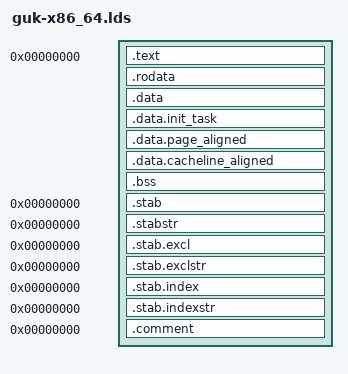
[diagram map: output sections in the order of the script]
/*
 * Copyright (c) 2009, 2011, Oracle and/or its affiliates. All rights reserved.
 * DO NOT ALTER OR REMOVE COPYRIGHT NOTICES OR THIS FILE HEADER.
 *
 * This code is free software; you can redistribute it and/or modify it
 * under the terms of the GNU General Public License version 2 only, as
 * published by the Free Software Foundation.
 *
 * This code is distributed in the hope that it will be useful, but WITHOUT
 * ANY WARRANTY; without even the implied warranty of MERCHANTABILITY or
 * FITNESS FOR A PARTICULAR PURPOSE.  See the GNU General Public License
 * version 2 for more details (a copy is included in the LICENSE file that
 * accompanied this code).
 *
 * You should have received a copy of the GNU General Public License version
 * 2 along with this work; if not, write to the Free Software Foundation,
 * Inc., 51 Franklin St, Fifth Floor, Boston, MA 02110-1301 USA.
 *
 * Please contact Oracle, 500 Oracle Parkway, Redwood Shores, CA 94065 USA
 * or visit www.oracle.com if you need additional information or have any
 * questions.
 */
OUTPUT_FORMAT("elf64-x86-64", "elf64-x86-64", "elf64-x86-64")
OUTPUT_ARCH(i386:x86-64)
ENTRY(_start)
SECTIONS
{
  . = 0x00000000;
  _text = .;			/* Text and read-only data */
  .text : { 

      *(.text)
	      . = ALIGN(8);
	  __init_start = .;
      *(.GUK_init)
	  __init_end = .;
	  *(.gnu.warning)
  } = 0x9090

  _etext = .;			/* End of text section */

  .rodata : { *(.rodata) *(.rodata.*) }

  .data : {			/* Data */
	*(.data)
	CONSTRUCTORS
	}

  _edata = .;			/* End of data section */

  . = ALIGN(8192);		/* init_task */
  .data.init_task : { *(.data.init_task) }

  . = ALIGN(4096);
  .data.page_aligned : { *(.data.idt) }

  . = ALIGN(32);
  .data.cacheline_aligned : { *(.data.cacheline_aligned) }

  __bss_start = .;		/* BSS */
  .bss : {
	*(.bss)
	}
  _end = . ;

  /* Sections to be discarded */
  /DISCARD/ : {
	*(.text.exit)
	*(.data.exit)
	*(.exitcall.exit)
	}

  /* Stabs debugging sections.  */
  .stab 0 : { *(.stab) }
  .stabstr 0 : { *(.stabstr) }
  .stab.excl 0 : { *(.stab.excl) }
  .stab.exclstr 0 : { *(.stab.exclstr) }
  .stab.index 0 : { *(.stab.index) }
  .stab.indexstr 0 : { *(.stab.indexstr) }
  .comment 0 : { *(.comment) }
}
